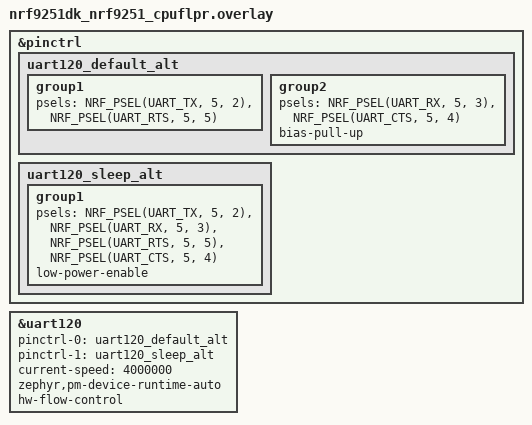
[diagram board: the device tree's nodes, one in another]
/*
 * Copyright (c) 2026 Nordic Semiconductor ASA
 *
 * SPDX-License-Identifier: LicenseRef-Nordic-5-Clause
 */

/* Test requires loopbacks:
 * TX-RX: P5.02 - P5.03
 * RTS-CTS: P5.04 - P5.05
 */

&pinctrl {
	uart120_default_alt: uart120_default_alt {
		group1 {
			psels = <NRF_PSEL(UART_TX, 5, 2)>,
				<NRF_PSEL(UART_RTS, 5, 5)>;
		};

		group2 {
			psels = <NRF_PSEL(UART_RX, 5, 3)>,
				<NRF_PSEL(UART_CTS, 5, 4)>;
			bias-pull-up;
		};
	};

	uart120_sleep_alt: uart120_sleep_alt {
		group1 {
			psels = <NRF_PSEL(UART_TX, 5, 2)>,
				<NRF_PSEL(UART_RX, 5, 3)>,
				<NRF_PSEL(UART_RTS, 5, 5)>,
				<NRF_PSEL(UART_CTS, 5, 4)>;
			low-power-enable;
		};
	};
};

dut: &uart120 {
	status = "okay";
	pinctrl-0 = <&uart120_default_alt>;
	pinctrl-1 = <&uart120_sleep_alt>;
	pinctrl-names = "default", "sleep";
	current-speed = <4000000>;
	zephyr,pm-device-runtime-auto;
	/delete-property/ memory-regions;
	hw-flow-control;
};
